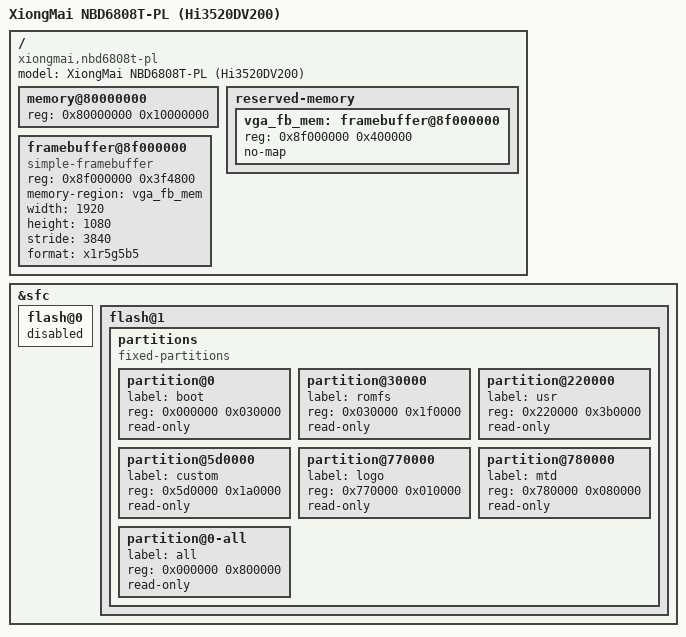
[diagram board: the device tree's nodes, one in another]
// SPDX-License-Identifier: (GPL-2.0-or-later OR MIT)
/*
 * XiongMai NBD6808T-PL NVR (MBD0157 board), Hi3520DV200, 8 MB SPI NOR.
 */

/dts-v1/;
#include "hi3520dv200-generic.dts"

/ {
	model = "XiongMai NBD6808T-PL (Hi3520DV200)";
	compatible = "xiongmai,nbd6808t-pl", "hisilicon,hi3520dv200";

	/*
	 * 256 MB of DDR. The vendor firmware gave Linux the first 128 MB and
	 * the rest to the media memory zone; without the MPP all of it is
	 * ordinary memory except the VGA framebuffer reserved below.
	 */
	memory@80000000 {
		device_type = "memory";
		reg = <0x80000000 0x10000000>;
	};

	reserved-memory {
		#address-cells = <1>;
		#size-cells = <1>;
		ranges;

		vga_fb_mem: framebuffer@8f000000 {
			reg = <0x8f000000 0x400000>;
			no-map;
		};
	};

	/*
	 * VGA, 1920x1080@60. The vendor bootloader drives the display
	 * controller ("startvo 0 4 10; startgx 0 0x8f000000 3840 0 0 1920
	 * 1080" opens VGA at 1080p60 and graphics layer 0 at this buffer,
	 * scanned out as ARGB1555 with the alpha bit ignored); Linux only
	 * draws into it. Without those bootloader commands nothing is shown.
	 */
	framebuffer@8f000000 {
		compatible = "simple-framebuffer";
		reg = <0x8f000000 0x3f4800>;
		memory-region = <&vga_fb_mem>;
		width = <1920>;
		height = <1080>;
		stride = <3840>;
		format = "x1r5g5b5";
	};
};

/*
 * 8 MB MX25L6406E on CS1. The partitions below are the stock firmware's
 * layout, read-only; they only apply when the bootloader passes no
 * "mtdparts=hi_sfc:..." of its own.
 */
&sfc {
	/* nothing is fitted on CS0 */
	flash@0 {
		status = "disabled";
	};

	flash@1 {
		partitions {
			compatible = "fixed-partitions";
			#address-cells = <1>;
			#size-cells = <1>;

			partition@0 {
				label = "boot";
				reg = <0x000000 0x030000>;
				read-only;
			};
			partition@30000 {
				label = "romfs";
				reg = <0x030000 0x1f0000>;
				read-only;
			};
			partition@220000 {
				label = "usr";
				reg = <0x220000 0x3b0000>;
				read-only;
			};
			partition@5d0000 {
				label = "custom";
				reg = <0x5d0000 0x1a0000>;
				read-only;
			};
			partition@770000 {
				label = "logo";
				reg = <0x770000 0x010000>;
				read-only;
			};
			partition@780000 {
				label = "mtd";
				reg = <0x780000 0x080000>;
				read-only;
			};
			/* the whole chip, for verifying it against a backup */
			partition@0-all {
				label = "all";
				reg = <0x000000 0x800000>;
				read-only;
			};
		};
	};
};
